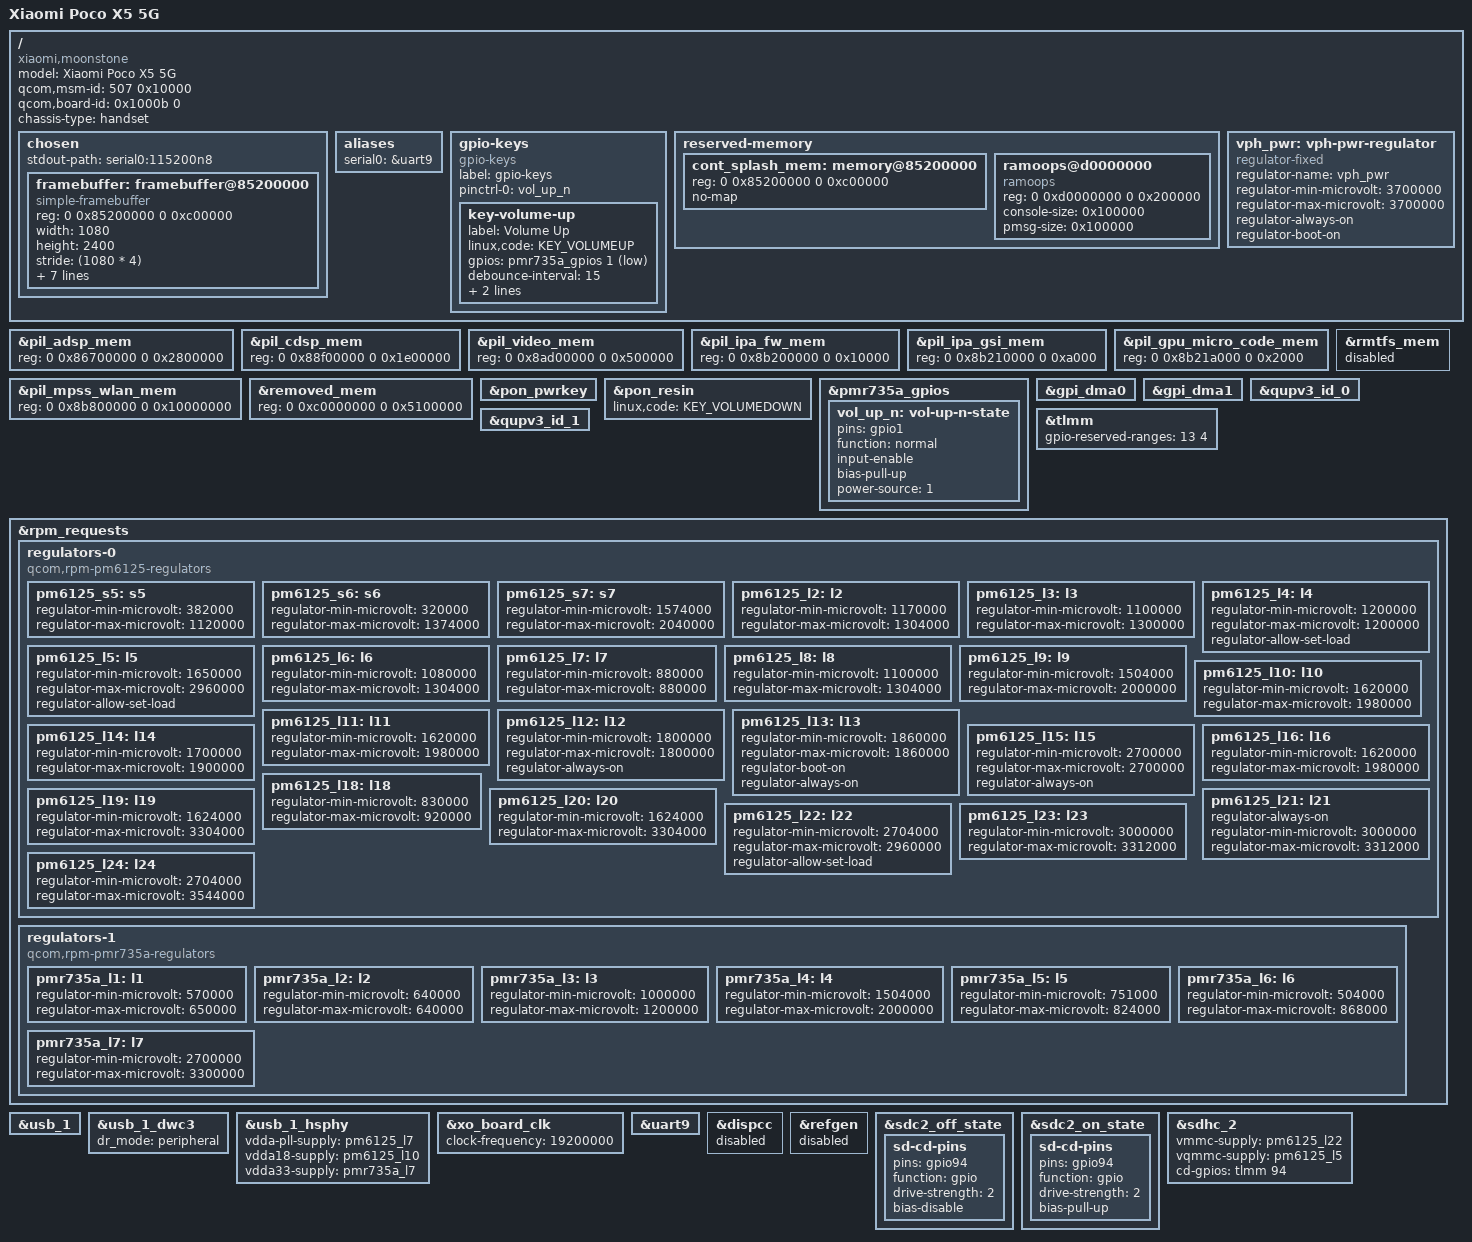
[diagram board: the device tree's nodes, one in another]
// SPDX-License-Identifier: BSD-3-Clause
/*
 * Copyright (c) 2026, Thanvir Diouf <tandiouf@gmail.com>
 */

/dts-v1/;

/* PMK8350 is configured to use SID6 instead of 0 */
#define PMK8350_SID 6

#include <dt-bindings/gpio/gpio.h>
#include <dt-bindings/input/input.h>
#include "sm6375.dtsi"
#include "pm6125.dtsi"
#include "pmk8350.dtsi"
#include "pmr735a.dtsi"

/* PM6125 PON is used and we can't have duplicate labels */
/delete-node/ &pmk8350_pon;

/ {
	model = "Xiaomi Poco X5 5G";
	compatible = "xiaomi,moonstone", "qcom,sm6375";

	/* Required by Qualcomm ABL to validate the DTB */
	qcom,msm-id = <507 0x10000>;
	qcom,board-id = <0x1000b 0>;

	chassis-type = "handset";

	chosen {
		stdout-path = "serial0:115200n8";

		#address-cells = <2>;
		#size-cells = <2>;
		ranges;

		framebuffer: framebuffer@85200000 {
			compatible = "simple-framebuffer";
			reg = <0 0x85200000 0 0xc00000>;

			width = <1080>;
			height = <2400>;
			stride = <(1080 * 4)>;
			format = "a8r8g8b8";
			vdda-supply = <&pm6125_l4>;
			vddio-supply = <&pm6125_l13>;
			/* Preserve the bootloader scanout during diagnostic bring-up. */
			clocks = <&gcc GCC_DISP_AHB_CLK>,
				 <&gcc GCC_DISP_HF_AXI_CLK>,
				 <&gcc GCC_DISP_THROTTLE_CORE_CLK>,
				 <&gcc GCC_DISP_GPLL0_DIV_CLK_SRC>;
		};
	};

	aliases {
		serial0 = &uart9;
	};

	gpio-keys {
		compatible = "gpio-keys";
		label = "gpio-keys";

		pinctrl-0 = <&vol_up_n>;
		pinctrl-names = "default";

		key-volume-up {
			label = "Volume Up";
			linux,code = <KEY_VOLUMEUP>;
			gpios = <&pmr735a_gpios 1 GPIO_ACTIVE_LOW>;
			debounce-interval = <15>;
			linux,can-disable;
			wakeup-source;
		};
	};

	reserved-memory {
		cont_splash_mem: memory@85200000 {
			reg = <0 0x85200000 0 0xc00000>;
			no-map;
		};

		ramoops@d0000000 {
			compatible = "ramoops";
			reg = <0 0xd0000000 0 0x200000>;
			/* Match moonstone.dts so Android/recovery can read the log. */
			console-size = <0x100000>;
			pmsg-size = <0x100000>;
		};
	};

	vph_pwr: vph-pwr-regulator {
		compatible = "regulator-fixed";
		regulator-name = "vph_pwr";
		regulator-min-microvolt = <3700000>;
		regulator-max-microvolt = <3700000>;
		regulator-always-on;
		regulator-boot-on;
	};
};

/* PIL memory region overrides matching stock Moonstone layout. */
&pil_adsp_mem {
	reg = <0 0x86700000 0 0x2800000>;
};

&pil_cdsp_mem {
	reg = <0 0x88f00000 0 0x1e00000>;
};

&pil_video_mem {
	reg = <0 0x8ad00000 0 0x500000>;
};

&pil_ipa_fw_mem {
	reg = <0 0x8b200000 0 0x10000>;
};

&pil_ipa_gsi_mem {
	reg = <0 0x8b210000 0 0xa000>;
};

&pil_gpu_micro_code_mem {
	reg = <0 0x8b21a000 0 0x2000>;
};

&pil_mpss_wlan_mem {
	reg = <0 0x8b800000 0 0x10000000>;
};

&removed_mem {
	reg = <0 0xc0000000 0 0x5100000>;
};

/* No modem boot yet; do not assign the inherited RMTFS region to the modem. */
&rmtfs_mem {
	status = "disabled";
};

&pon_pwrkey {
	status = "okay";
};

&pon_resin {
	status = "okay";
	linux,code = <KEY_VOLUMEDOWN>;
};

&pmr735a_gpios {
	vol_up_n: vol-up-n-state {
		pins = "gpio1";
		function = "normal";
		input-enable;
		bias-pull-up;
		power-source = <1>;
	};
};

&gpi_dma0 {
	status = "okay";
};

&gpi_dma1 {
	status = "okay";
};

&qupv3_id_0 {
	status = "okay";
};

&qupv3_id_1 {
	status = "okay";
};

&tlmm {
	gpio-reserved-ranges = <13 4>;
};

/*
 * Remote processors and Bluetooth stay disabled until firmware and rails
 * have been verified. They are not needed for the diagnostic USB boot.
 */

&rpm_requests {
	regulators-0 {
		compatible = "qcom,rpm-pm6125-regulators";

		pm6125_s5: s5 {
			regulator-min-microvolt = <382000>;
			regulator-max-microvolt = <1120000>;
		};

		pm6125_s6: s6 {
			regulator-min-microvolt = <320000>;
			regulator-max-microvolt = <1374000>;
		};

		pm6125_s7: s7 {
			regulator-min-microvolt = <1574000>;
			regulator-max-microvolt = <2040000>;
		};

		/*
		 * S8 is VDD_GFX
		 * L1 is VDD_LPI_CX
		 */

		pm6125_l2: l2 {
			regulator-min-microvolt = <1170000>;
			regulator-max-microvolt = <1304000>;
		};

		pm6125_l3: l3 {
			regulator-min-microvolt = <1100000>;
			regulator-max-microvolt = <1300000>;
		};

		pm6125_l4: l4 {
			regulator-min-microvolt = <1200000>;
			regulator-max-microvolt = <1200000>;
			regulator-allow-set-load;
		};

		pm6125_l5: l5 {
			regulator-min-microvolt = <1650000>;
			regulator-max-microvolt = <2960000>;
			regulator-allow-set-load;
		};

		pm6125_l6: l6 {
			regulator-min-microvolt = <1080000>;
			regulator-max-microvolt = <1304000>;
		};

		pm6125_l7: l7 {
			regulator-min-microvolt = <880000>;
			regulator-max-microvolt = <880000>;
		};

		pm6125_l8: l8 {
			regulator-min-microvolt = <1100000>;
			regulator-max-microvolt = <1304000>;
		};

		pm6125_l9: l9 {
			regulator-min-microvolt = <1504000>;
			regulator-max-microvolt = <2000000>;
		};

		pm6125_l10: l10 {
			regulator-min-microvolt = <1620000>;
			regulator-max-microvolt = <1980000>;
		};

		pm6125_l11: l11 {
			regulator-min-microvolt = <1620000>;
			regulator-max-microvolt = <1980000>;
		};

		pm6125_l12: l12 {
			regulator-min-microvolt = <1800000>;
			regulator-max-microvolt = <1800000>;
			regulator-always-on;
		};

		pm6125_l13: l13 {
			regulator-min-microvolt = <1860000>;
			regulator-max-microvolt = <1860000>;
			regulator-boot-on;
			regulator-always-on;
		};

		pm6125_l14: l14 {
			regulator-min-microvolt = <1700000>;
			regulator-max-microvolt = <1900000>;
		};

		pm6125_l15: l15 {
			regulator-min-microvolt = <2700000>;
			regulator-max-microvolt = <2700000>;
			regulator-always-on;
		};

		pm6125_l16: l16 {
			regulator-min-microvolt = <1620000>;
			regulator-max-microvolt = <1980000>;
		};

		/* L17 is VDD_LPI_MX */

		pm6125_l18: l18 {
			regulator-min-microvolt = <830000>;
			regulator-max-microvolt = <920000>;
		};

		pm6125_l19: l19 {
			regulator-min-microvolt = <1624000>;
			regulator-max-microvolt = <3304000>;
		};

		pm6125_l20: l20 {
			regulator-min-microvolt = <1624000>;
			regulator-max-microvolt = <3304000>;
		};

		pm6125_l21: l21 {
			regulator-always-on;
			regulator-min-microvolt = <3000000>;
			regulator-max-microvolt = <3312000>;
		};

		pm6125_l22: l22 {
			regulator-min-microvolt = <2704000>;
			regulator-max-microvolt = <2960000>;
			regulator-allow-set-load;
		};

		pm6125_l23: l23 {
			regulator-min-microvolt = <3000000>;
			regulator-max-microvolt = <3312000>;
		};

		pm6125_l24: l24 {
			regulator-min-microvolt = <2704000>;
			regulator-max-microvolt = <3544000>;
		};
	};

	regulators-1 {
		compatible = "qcom,rpm-pmr735a-regulators";

		/*
		 * S1 is VDD_MX
		 * S2 is VDD_CX
		 */

		pmr735a_l1: l1 {
			regulator-min-microvolt = <570000>;
			regulator-max-microvolt = <650000>;
		};

		pmr735a_l2: l2 {
			regulator-min-microvolt = <640000>;
			regulator-max-microvolt = <640000>;
		};

		pmr735a_l3: l3 {
			regulator-min-microvolt = <1000000>;
			regulator-max-microvolt = <1200000>;
		};

		pmr735a_l4: l4 {
			regulator-min-microvolt = <1504000>;
			regulator-max-microvolt = <2000000>;
		};

		pmr735a_l5: l5 {
			regulator-min-microvolt = <751000>;
			regulator-max-microvolt = <824000>;
		};

		pmr735a_l6: l6 {
			regulator-min-microvolt = <504000>;
			regulator-max-microvolt = <868000>;
		};

		pmr735a_l7: l7 {
			regulator-min-microvolt = <2700000>;
			regulator-max-microvolt = <3300000>;
		};
	};
};


&usb_1 {
	status = "okay";
};

&usb_1_dwc3 {
	dr_mode = "peripheral";
};

&usb_1_hsphy {
	vdda-pll-supply = <&pm6125_l7>;
	vdda18-supply = <&pm6125_l10>;
	vdda33-supply = <&pmr735a_l7>;
	status = "okay";
};

&xo_board_clk {
	clock-frequency = <19200000>;
};

&uart9 {
	status = "okay";
};

/* Keep DISPCC from reprogramming the bootloader PLL in the USB-first DTB. */
&dispcc {
	status = "disabled";
};

&refgen {
	status = "disabled";
};

&sdc2_off_state {
	sd-cd-pins {
		pins = "gpio94";
		function = "gpio";
		drive-strength = <2>;
		bias-disable;
	};
};

&sdc2_on_state {
	sd-cd-pins {
		pins = "gpio94";
		function = "gpio";
		drive-strength = <2>;
		bias-pull-up;
	};
};

&sdhc_2 {
	vmmc-supply = <&pm6125_l22>;
	vqmmc-supply = <&pm6125_l5>;
	/* Moonstone overrides the QRD card-detect polarity. */
	cd-gpios = <&tlmm 94 GPIO_ACTIVE_HIGH>;
	status = "okay";
};
